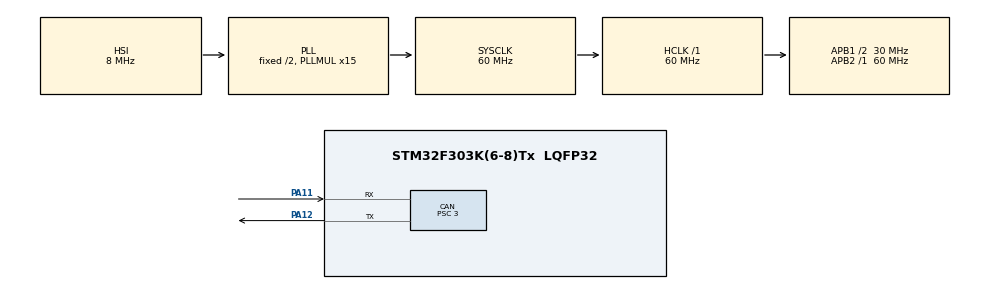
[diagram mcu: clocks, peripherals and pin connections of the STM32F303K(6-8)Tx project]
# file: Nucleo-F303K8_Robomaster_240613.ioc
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CAN.BS1=CAN_BS1_6TQ
CAN.BS2=CAN_BS2_3TQ
CAN.CalculateBaudRate=1000000
CAN.CalculateTimeBit=1000
CAN.CalculateTimeQuantum=100.0
CAN.Prescaler=3
Mcu.Family=STM32F3
Mcu.Name=STM32F303K(6-8)Tx
Mcu.Package=LQFP32
NVIC.CAN_RX0_IRQn=true\:0\:0\:false\:false\:true\:true\:true\:true
NVIC.PriorityGroup=NVIC_PRIORITYGROUP_4
PA11.Mode=CAN_Activate
PA11.Signal=CAN_RX
PA12.Mode=CAN_Activate
PA12.Signal=CAN_TX
PA13.GPIO_Label=SWDIO
PA13.Mode=Serial_Wire
PA13.Signal=SYS_JTMS-SWDIO
PA14.GPIO_Label=SWCLK
PA14.Mode=Serial_Wire
PA14.Signal=SYS_JTCK-SWCLK
PA15.GPIO_Label=VCP_RX
PA15.Signal=USART2_RX
PA2.GPIO_Label=VCP_TX
PA2.Signal=USART2_TX
PF0\ /\ OSC_IN.GPIO_Label=MCO
PF0\ /\ OSC_IN.Signal=RCC_OSC_IN
ProjectManager.HeapSize=0x200
ProjectManager.StackSize=0x400
ProjectManager.TargetToolchain=STM32CubeIDE
RCC.AHBFreq_Value=60000000
RCC.APB1CLKDivider=RCC_HCLK_DIV2
RCC.APB1Freq_Value=30000000
RCC.APB1TimFreq_Value=60000000
RCC.APB2Freq_Value=60000000
RCC.APB2TimFreq_Value=60000000
RCC.CortexFreq_Value=60000000
RCC.HCLKFreq_Value=60000000
RCC.HSE_VALUE=8000000
RCC.HSI_VALUE=8000000
RCC.PLLMUL=RCC_PLL_MUL15
RCC.SYSCLKFreq_VALUE=60000000
RCC.SYSCLKSourceVirtual=RCC_SYSCLKSOURCE_PLLCLK
board=NUCLEO-F303K8

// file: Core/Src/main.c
/* USER CODE BEGIN Header */
/**
 ******************************************************************************
 * @file           : main.c
 * @brief          : Main program body
 ******************************************************************************
 * @attention
 *
 * Copyright (c) 2024 STMicroelectronics.
 * All rights reserved.
 *
 * This software is licensed under terms that can be found in the LICENSE file
 * in the root directory of this software component.
 * If no LICENSE file comes with this software, it is provided AS-IS.
 *
 ******************************************************************************
 */
/* USER CODE END Header */
#include "main.h"

/* USER CODE BEGIN Includes */
#include <stdio.h>

/* USER CODE END Includes */

CAN_HandleTypeDef hcan;

/* USER CODE BEGIN PV */
// 制御用
// 角速度[rpm]（0番目は使わない）
int16_t rpm[9] = {0};
// 目標角速度[rpm]（テスト用，0番目は使わない）
int16_t rpm_target[9] = {0};
// 入力トルク（0番目は使わない）
int16_t torque_input[9] = {0};

// 送信用
CAN_TxHeaderTypeDef TxHeader;
uint32_t TxMailbox;
uint8_t TxData[8];

// 受信用
CAN_FilterTypeDef filter;
uint32_t id;
uint32_t dlc;
uint8_t data[8];

// 受信時割り込み（実質的な処理）
void HAL_CAN_RxFifo0MsgPendingCallback(CAN_HandleTypeDef *hcan) {
	CAN_RxHeaderTypeDef RxHeader;
	uint8_t RxData[8];
	if (HAL_CAN_GetRxMessage(hcan, CAN_RX_FIFO0, &RxHeader, RxData) == HAL_OK) {
		id = (RxHeader.IDE == CAN_ID_STD) ? RxHeader.StdId : RxHeader.ExtId; // ID
		dlc = RxHeader.DLC; // DLC
		data[0] = RxData[0]; // Data
		data[1] = RxData[1];
		data[2] = RxData[2];
		data[3] = RxData[3];
		data[4] = RxData[4];
		data[5] = RxData[5];
		data[6] = RxData[6];
		data[7] = RxData[7];
	}
	// CAN IDをマスクして変数の格納先指定
	// 例: id = 0x202 ==> id & 0x00F = 2
	if(id >= 0x200) {
		uint32_t motor_id = id & 0x00F;
		rpm[motor_id] = data[2] << 8 | data[3];
//		// P制御
//		// モータ1の目標角速度
//		rpm_target[1] = -5000;
//		// -16384 <= torque_input <= 16384
//		torque_input[1] = (int16_t)(1.0 * (rpm_target[1] - rpm[1]));
	}
}

/* USER CODE END PV */

void SystemClock_Config(void);
static void MX_GPIO_Init(void);
static void MX_CAN_Init(void);

int main(void) {

	/* MCU Configuration--------------------------------------------------------*/

	/* Reset of all peripherals, Initializes the Flash interface and the Systick. */
	HAL_Init();

	/* Configure the system clock */
	SystemClock_Config();

	/* Initialize all configured peripherals */
	MX_GPIO_Init();
	MX_CAN_Init();
	/* USER CODE BEGIN 2 */
	// 送信用初期設定
	TxHeader.StdId = 0x200;                 // CAN ID
	TxHeader.RTR = CAN_RTR_DATA;            // フレー�?タイプ�?��?ータフレー�?
	TxHeader.IDE = CAN_ID_STD;              // 標準ID(11?��ﾞｯ?�?)
	TxHeader.DLC = 8;                       // �?ータ長は8バイトに
	TxHeader.TransmitGlobalTime = DISABLE;  // ???

	// 受信用初期設定
	// フィルタ設定初期設定
	uint32_t fId = 0x200 << 21;        // フィルターID
	uint32_t fMask = (0x200 << 21) | 0x4; // フィルターマスク（0x4はビット埋め用）
	filter.FilterIdHigh = fId >> 16;             // フィルターIDの上位16ビット
	filter.FilterIdLow = fId;                   // フィルターIDの下位16ビット
	filter.FilterMaskIdHigh = fMask >> 16;           // フィルターマスクの上位16ビット
	filter.FilterMaskIdLow = fMask;                 // フィルターマスクの下位16ビット
	filter.FilterScale = CAN_FILTERSCALE_32BIT; // 32モード
	filter.FilterFIFOAssignment = CAN_FILTER_FIFO0;      // FIFO0へ格納
	filter.FilterBank = 0;
	filter.FilterMode = CAN_FILTERMODE_IDMASK; // IDマスクモード
	filter.SlaveStartFilterBank = 14;
	filter.FilterActivation = ENABLE;
	// フィルタ初期設定適用
	HAL_CAN_ConfigFilter(&hcan, &filter);

	// 割り込み有効
	HAL_CAN_ActivateNotification(&hcan, CAN_IT_RX_FIFO0_MSG_PENDING);

	// CANスタート
	HAL_CAN_Start(&hcan);

	/* USER CODE END 2 */

	/* Infinite loop */
	while (1) {
		// データ送信
		torque_input[1] = 1000;
		torque_input[2] = 1000;
		if (0 < HAL_CAN_GetTxMailboxesFreeLevel(&hcan)) {
			TxData[0] = (torque_input[1] >> 8) & 0xFF;
			TxData[1] = torque_input[1] & 0xFF;
			TxData[2] = (torque_input[2] >> 8) & 0xFF;
			TxData[3] = torque_input[2] & 0xFF;
			TxData[4] = 0x00;
			TxData[5] = 0x00;
			TxData[6] = 0x00;
			TxData[7] = 0x00;
			HAL_CAN_AddTxMessage(&hcan, &TxHeader, TxData, &TxMailbox);
		}

	}
}

void SystemClock_Config(void) {
	RCC_OscInitTypeDef RCC_OscInitStruct = { 0 };
	RCC_ClkInitTypeDef RCC_ClkInitStruct = { 0 };

	/** Initializes the RCC Oscillators according to the specified parameters
	 * in the RCC_OscInitTypeDef structure.
	 */
	RCC_OscInitStruct.OscillatorType = RCC_OSCILLATORTYPE_HSI;
	RCC_OscInitStruct.HSIState = RCC_HSI_ON;
	RCC_OscInitStruct.HSICalibrationValue = RCC_HSICALIBRATION_DEFAULT;
	RCC_OscInitStruct.PLL.PLLState = RCC_PLL_ON;
	RCC_OscInitStruct.PLL.PLLSource = RCC_PLLSOURCE_HSI;
	RCC_OscInitStruct.PLL.PLLMUL = RCC_PLL_MUL15;
	if (HAL_RCC_OscConfig(&RCC_OscInitStruct) != HAL_OK) {
		Error_Handler();
	}

	/** Initializes the CPU, AHB and APB buses clocks
	 */
	RCC_ClkInitStruct.ClockType = RCC_CLOCKTYPE_HCLK | RCC_CLOCKTYPE_SYSCLK
			| RCC_CLOCKTYPE_PCLK1 | RCC_CLOCKTYPE_PCLK2;
	RCC_ClkInitStruct.SYSCLKSource = RCC_SYSCLKSOURCE_PLLCLK;
	RCC_ClkInitStruct.AHBCLKDivider = RCC_SYSCLK_DIV1;
	RCC_ClkInitStruct.APB1CLKDivider = RCC_HCLK_DIV2;
	RCC_ClkInitStruct.APB2CLKDivider = RCC_HCLK_DIV1;

	if (HAL_RCC_ClockConfig(&RCC_ClkInitStruct, FLASH_LATENCY_2) != HAL_OK) {
		Error_Handler();
	}
}

static void MX_CAN_Init(void) {

	hcan.Instance = CAN;
	hcan.Init.Prescaler = 3;
	hcan.Init.Mode = CAN_MODE_NORMAL;
	hcan.Init.SyncJumpWidth = CAN_SJW_1TQ;
	hcan.Init.TimeSeg1 = CAN_BS1_6TQ;
	hcan.Init.TimeSeg2 = CAN_BS2_3TQ;
	hcan.Init.TimeTriggeredMode = DISABLE;
	hcan.Init.AutoBusOff = DISABLE;
	hcan.Init.AutoWakeUp = DISABLE;
	hcan.Init.AutoRetransmission = DISABLE;
	hcan.Init.ReceiveFifoLocked = DISABLE;
	hcan.Init.TransmitFifoPriority = DISABLE;
	if (HAL_CAN_Init(&hcan) != HAL_OK) {
		Error_Handler();
	}

}

static void MX_GPIO_Init(void) {
	GPIO_InitTypeDef GPIO_InitStruct = { 0 };

	/* GPIO Ports Clock Enable */
	__HAL_RCC_GPIOF_CLK_ENABLE();
	__HAL_RCC_GPIOA_CLK_ENABLE();

	/*Configure GPIO pins : VCP_TX_Pin VCP_RX_Pin */
	GPIO_InitStruct.Pin = VCP_TX_Pin | VCP_RX_Pin;
	GPIO_InitStruct.Mode = GPIO_MODE_AF_PP;
	GPIO_InitStruct.Pull = GPIO_NOPULL;
	GPIO_InitStruct.Speed = GPIO_SPEED_FREQ_HIGH;
	GPIO_InitStruct.Alternate = GPIO_AF7_USART2;
	HAL_GPIO_Init(GPIOA, &GPIO_InitStruct);

}

void Error_Handler(void) {
	__disable_irq();
	while (1) {
	}
}
